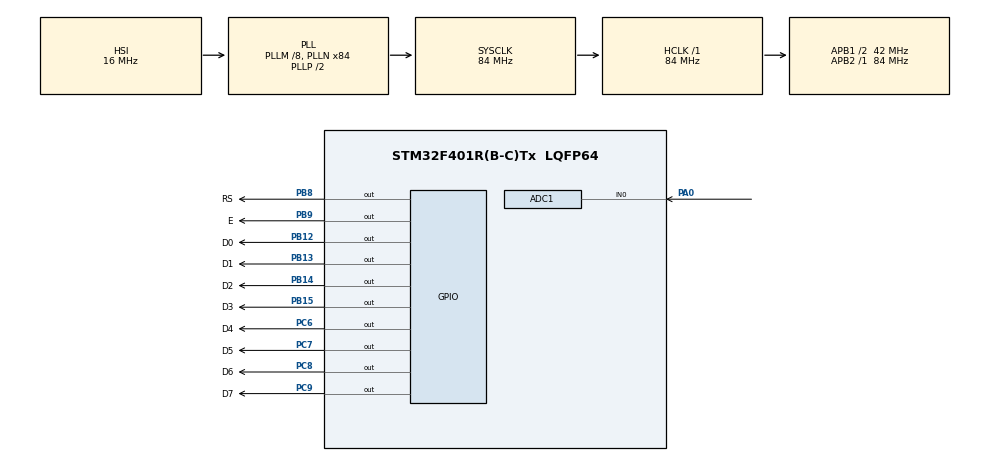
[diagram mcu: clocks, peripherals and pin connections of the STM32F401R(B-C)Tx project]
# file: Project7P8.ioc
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Mcu.Family=STM32F4
RCC.CortexFreq_Value=84000000
ADC1.Rank-0\#ChannelRegularConversion=1
PB9.GPIO_Label=E
PC9.GPIO_Label=D7
PB14.GPIO_Label=D2
PC8.Signal=GPIO_Output
PC6.Signal=GPIO_Output
PC6.GPIO_Label=D4
RCC.APB1CLKDivider=RCC_HCLK_DIV2
PB13.GPIO_Label=D1
PB15.Signal=GPIO_Output
PB13.Signal=GPIO_Output
RCC.SYSCLKSource=RCC_SYSCLKSOURCE_PLLCLK
ProjectManager.StackSize=0x400
PA0-WKUP.Signal=ADCx_IN0
PC8.GPIO_Label=D6
PB8.GPIO_Label=RS
ProjectManager.TargetToolchain=STM32CubeIDE
RCC.HCLKFreq_Value=84000000
RCC.APB2TimFreq_Value=84000000
PC7.Signal=GPIO_Output
RCC.LSE_VALUE=32768
RCC.AHBFreq_Value=84000000
PB14.Signal=GPIO_Output
ADC1.Channel-0\#ChannelRegularConversion=ADC_CHANNEL_0
RCC.HSE_VALUE=25000000
board=custom
RCC.VCOOutputFreq_Value=168000000
PB12.GPIO_Label=D0
RCC.APB2Freq_Value=84000000
PB15.GPIO_Label=D3
SH.ADCx_IN0.0=ADC1_IN0,IN0
Mcu.Name=STM32F401R(B-C)Tx
ADC1.SamplingTime-0\#ChannelRegularConversion=ADC_SAMPLETIME_3CYCLES
PC7.GPIO_Label=D5
RCC.48MHZClocksFreq_Value=42000000
RCC.SYSCLKFreq_VALUE=84000000
Mcu.Package=LQFP64
PB9.Signal=GPIO_Output
ADC1.master=1
ProjectManager.HeapSize=0x200
RCC.HSI_VALUE=16000000
NVIC.PriorityGroup=NVIC_PRIORITYGROUP_4
ADC1.NbrOfConversionFlag=1
RCC.PLLM=8
RCC.PLLN=84
RCC.APB1TimFreq_Value=84000000
PB8.Signal=GPIO_Output
PC9.Signal=GPIO_Output
RCC.APB1Freq_Value=42000000
PB12.Signal=GPIO_Output

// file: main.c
/* USER CODE BEGIN Header */
/**
  ******************************************************************************
  * @file           : main.c
  * @brief          : Main program body
  ******************************************************************************
  * @attention
  *
  * <h2><center>&copy; Copyright (c) 2021 STMicroelectronics.
  * All rights reserved.</center></h2>
  *
  * This software component is licensed by ST under BSD 3-Clause license,
  * the "License"; You may not use this file except in compliance with the
  * License. You may obtain a copy of the License at:
  *                        opensource.org/licenses/BSD-3-Clause
  *
  ******************************************************************************
  */
/* USER CODE END Header */
#include "main.h"

/* USER CODE BEGIN Includes */
#include "STM_MY_LCD16X2.h"
/* USER CODE END Includes */

ADC_HandleTypeDef hadc1;

/* USER CODE BEGIN PV */
uint16_t raw;
float x;
float y;
/* USER CODE END PV */

void SystemClock_Config(void);
static void MX_GPIO_Init(void);
static void MX_ADC1_Init(void);

int main(void)
{

  /* MCU Configuration--------------------------------------------------------*/

  /* Reset of all peripherals, Initializes the Flash interface and the Systick. */
  HAL_Init();

  /* Configure the system clock */
  SystemClock_Config();

  /* Initialize all configured peripherals */
  MX_GPIO_Init();
  MX_ADC1_Init();

  /* Infinite loop */
  while (1)
  {
	  HAL_ADC_Start(&hadc1);
		  HAL_ADC_PollForConversion(&hadc1, 300);
		  raw = HAL_ADC_GetValue(&hadc1);
		  float vin = raw*(5.0/4096);
		  x=(vin-0.27)/0.01879+1;
		  LCD1602_Begin8BIT(RS_GPIO_Port, RS_Pin, E_Pin, D0_GPIO_Port, D0_Pin, D1_Pin, D2_Pin, D3_Pin, D4_GPIO_Port, D4_Pin, D5_Pin, D6_Pin, D7_Pin);
		  LCD1602_PrintInt(x);
		  LCD1602_2ndLine();
		  LCD1602_PrintFloat(vin,2);

  }
}

void SystemClock_Config(void)
{
  RCC_OscInitTypeDef RCC_OscInitStruct = {0};
  RCC_ClkInitTypeDef RCC_ClkInitStruct = {0};

  /** Configure the main internal regulator output voltage
  */
  __HAL_RCC_PWR_CLK_ENABLE();
  __HAL_PWR_VOLTAGESCALING_CONFIG(PWR_REGULATOR_VOLTAGE_SCALE2);
  /** Initializes the RCC Oscillators according to the specified parameters
  * in the RCC_OscInitTypeDef structure.
  */
  RCC_OscInitStruct.OscillatorType = RCC_OSCILLATORTYPE_HSI;
  RCC_OscInitStruct.HSIState = RCC_HSI_ON;
  RCC_OscInitStruct.HSICalibrationValue = RCC_HSICALIBRATION_DEFAULT;
  RCC_OscInitStruct.PLL.PLLState = RCC_PLL_ON;
  RCC_OscInitStruct.PLL.PLLSource = RCC_PLLSOURCE_HSI;
  RCC_OscInitStruct.PLL.PLLM = 8;
  RCC_OscInitStruct.PLL.PLLN = 84;
  RCC_OscInitStruct.PLL.PLLP = RCC_PLLP_DIV2;
  RCC_OscInitStruct.PLL.PLLQ = 4;
  if (HAL_RCC_OscConfig(&RCC_OscInitStruct) != HAL_OK)
  {
    Error_Handler();
  }
  /** Initializes the CPU, AHB and APB buses clocks
  */
  RCC_ClkInitStruct.ClockType = RCC_CLOCKTYPE_HCLK|RCC_CLOCKTYPE_SYSCLK
                              |RCC_CLOCKTYPE_PCLK1|RCC_CLOCKTYPE_PCLK2;
  RCC_ClkInitStruct.SYSCLKSource = RCC_SYSCLKSOURCE_PLLCLK;
  RCC_ClkInitStruct.AHBCLKDivider = RCC_SYSCLK_DIV1;
  RCC_ClkInitStruct.APB1CLKDivider = RCC_HCLK_DIV2;
  RCC_ClkInitStruct.APB2CLKDivider = RCC_HCLK_DIV1;

  if (HAL_RCC_ClockConfig(&RCC_ClkInitStruct, FLASH_LATENCY_2) != HAL_OK)
  {
    Error_Handler();
  }
}

static void MX_ADC1_Init(void)
{

  ADC_ChannelConfTypeDef sConfig = {0};

  /** Configure the global features of the ADC (Clock, Resolution, Data Alignment and number of conversion)
  */
  hadc1.Instance = ADC1;
  hadc1.Init.ClockPrescaler = ADC_CLOCK_SYNC_PCLK_DIV4;
  hadc1.Init.Resolution = ADC_RESOLUTION_12B;
  hadc1.Init.ScanConvMode = DISABLE;
  hadc1.Init.ContinuousConvMode = DISABLE;
  hadc1.Init.DiscontinuousConvMode = DISABLE;
  hadc1.Init.ExternalTrigConvEdge = ADC_EXTERNALTRIGCONVEDGE_NONE;
  hadc1.Init.ExternalTrigConv = ADC_SOFTWARE_START;
  hadc1.Init.DataAlign = ADC_DATAALIGN_RIGHT;
  hadc1.Init.NbrOfConversion = 1;
  hadc1.Init.DMAContinuousRequests = DISABLE;
  hadc1.Init.EOCSelection = ADC_EOC_SINGLE_CONV;
  if (HAL_ADC_Init(&hadc1) != HAL_OK)
  {
    Error_Handler();
  }
  /** Configure for the selected ADC regular channel its corresponding rank in the sequencer and its sample time.
  */
  sConfig.Channel = ADC_CHANNEL_0;
  sConfig.Rank = 1;
  sConfig.SamplingTime = ADC_SAMPLETIME_3CYCLES;
  if (HAL_ADC_ConfigChannel(&hadc1, &sConfig) != HAL_OK)
  {
    Error_Handler();
  }

}

static void MX_GPIO_Init(void)
{
  GPIO_InitTypeDef GPIO_InitStruct = {0};

  /* GPIO Ports Clock Enable */
  __HAL_RCC_GPIOA_CLK_ENABLE();
  __HAL_RCC_GPIOB_CLK_ENABLE();
  __HAL_RCC_GPIOC_CLK_ENABLE();

  /*Configure GPIO pin Output Level */
  HAL_GPIO_WritePin(GPIOB, D0_Pin|D1_Pin|D2_Pin|D3_Pin
                          |RS_Pin|E_Pin, GPIO_PIN_RESET);

  /*Configure GPIO pin Output Level */
  HAL_GPIO_WritePin(GPIOC, D4_Pin|D5_Pin|D6_Pin|D7_Pin, GPIO_PIN_RESET);

  /*Configure GPIO pins : D0_Pin D1_Pin D2_Pin D3_Pin
                           RS_Pin E_Pin */
  GPIO_InitStruct.Pin = D0_Pin|D1_Pin|D2_Pin|D3_Pin
                          |RS_Pin|E_Pin;
  GPIO_InitStruct.Mode = GPIO_MODE_OUTPUT_PP;
  GPIO_InitStruct.Pull = GPIO_NOPULL;
  GPIO_InitStruct.Speed = GPIO_SPEED_FREQ_LOW;
  HAL_GPIO_Init(GPIOB, &GPIO_InitStruct);

  /*Configure GPIO pins : D4_Pin D5_Pin D6_Pin D7_Pin */
  GPIO_InitStruct.Pin = D4_Pin|D5_Pin|D6_Pin|D7_Pin;
  GPIO_InitStruct.Mode = GPIO_MODE_OUTPUT_PP;
  GPIO_InitStruct.Pull = GPIO_NOPULL;
  GPIO_InitStruct.Speed = GPIO_SPEED_FREQ_LOW;
  HAL_GPIO_Init(GPIOC, &GPIO_InitStruct);

}

void Error_Handler(void)
{
  __disable_irq();
  while (1)
  {
  }
}

/************************ (C) COPYRIGHT STMicroelectronics *****END OF FILE****/
